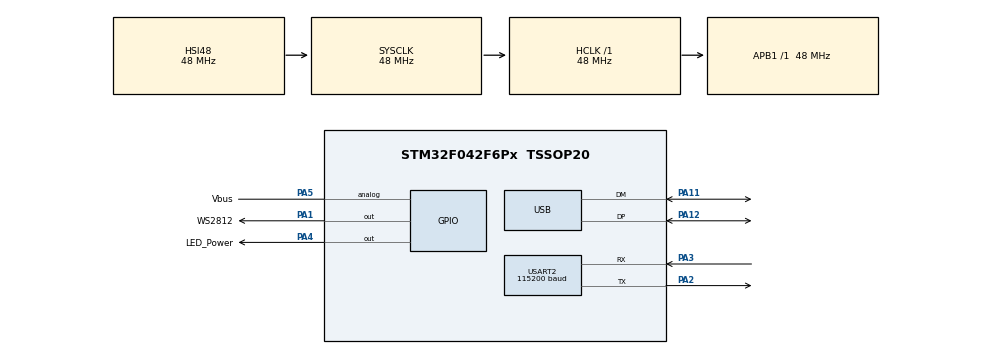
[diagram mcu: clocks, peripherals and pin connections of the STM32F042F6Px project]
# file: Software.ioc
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Mcu.Family=STM32F0
VP_SYS_VS_PINREMAP.Mode=PINREMAP
USB_DEVICE.CLASS_NAME_FS=CDC
NVIC.USB_IRQn=true\:0\:0\:false\:false\:true\:false\:true
USB_DEVICE.VirtualModeFS=Cdc_FS
VP_IWDG_VS_IWDG.Mode=IWDG_Activate
PA11.Mode=Device
USART2.BaudRate=115200
RCC.SYSCLKSource=RCC_SYSCLKSOURCE_HSI48
ProjectManager.StackSize=0x400
PA3.Mode=Asynchronous
PA13.Signal=SYS_SWDIO
PA12.Signal=USB_DP
PA4.PinState=GPIO_PIN_RESET
ProjectManager.TargetToolchain=Other Toolchains (GPDSC)
RCC.HCLKFreq_Value=48000000
VP_USB_DEVICE_VS_USB_DEVICE_CDC_FS.Mode=CDC_FS
VP_RCC_USB.Mode=CRS SYNC Source USB
PA1.GPIO_PuPd=GPIO_NOPULL
PA1.Signal=GPIO_Output
RCC.AHBFreq_Value=48000000
PF0-OSC_IN.Mode=HSE-External-Oscillator
PA5.Signal=SharedAnalog_PA5
PA4.GPIO_PuPd=GPIO_NOPULL
board=custom
USART2.VirtualMode-Asynchronous=VM_ASYNC
PA4.GPIO_Speed=GPIO_SPEED_FREQ_LOW
PA14.Mode=Serial_Wire
PA1.GPIO_Speed=GPIO_SPEED_FREQ_LOW
PA1.GPIO_Label=WS2812
PA13.Mode=Serial_Wire
Mcu.Name=STM32F042F6Px
PA2.Signal=USART2_TX
PA4.Signal=GPIO_Output
RCC.SYSCLKFreq_VALUE=48000000
Mcu.Package=TSSOP20
PA12.Mode=Device
PA5.GPIO_Label=Vbus
PA11.Signal=USB_DM
USB_DEVICE.APP_TX_DATA_SIZE=512
PA14.Signal=SYS_SWCLK
ProjectManager.HeapSize=0x200
PA1.PinState=GPIO_PIN_RESET
PA4.GPIO_ModeDefaultOutputPP=GPIO_MODE_OUTPUT_PP
SH.SharedAnalog_PA5.1=ADC_IN5
SH.SharedAnalog_PA5.0=GPIO_Analog
USB_DEVICE.APP_RX_DATA_SIZE=512
RCC.APB1TimFreq_Value=48000000
PA2.Mode=Asynchronous
PF0-OSC_IN.Signal=RCC_OSC_IN
PF1-OSC_OUT.Mode=HSE-External-Oscillator
RCC.APB1Freq_Value=48000000
USB_DEVICE.VirtualMode=Cdc
PA4.GPIO_Label=LED_Power
PF1-OSC_OUT.Signal=RCC_OSC_OUT
USB_DEVICE.USBD_DEBUG_LEVEL=2
PA3.Signal=USART2_RX
PA1.GPIO_ModeDefaultOutputPP=GPIO_MODE_OUTPUT_PP

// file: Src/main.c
/* USER CODE BEGIN Header */
/**
  ******************************************************************************
  * @file           : main.c
  * @brief          : Main program body
  ******************************************************************************
  * @attention
  *
  * <h2><center>&copy; Copyright (c) 2020 STMicroelectronics.
  * All rights reserved.</center></h2>
  *
  * This software component is licensed by ST under Ultimate Liberty license
  * SLA0044, the "License"; You may not use this file except in compliance with
  * the License. You may obtain a copy of the License at:
  *                             www.st.com/SLA0044
  *
  ******************************************************************************
  */
/* USER CODE END Header */

#include "main.h"
#include "iwdg.h"
#include "usart.h"
#include "usb_device.h"
#include "gpio.h"

void SystemClock_Config(void);

int main(void)
{

  /* MCU Configuration--------------------------------------------------------*/

  /* Reset of all peripherals, Initializes the Flash interface and the Systick. */
  HAL_Init();

  /* Configure the system clock */
  SystemClock_Config();

  /* Initialize all configured peripherals */
  MX_GPIO_Init();
  //MX_IWDG_Init();
  MX_USART2_UART_Init();
  MX_USB_DEVICE_Init();

  /* Infinite loop */
  /* USER CODE BEGIN WHILE */
  while (1)
  {
    //HAL_GPIO_WritePin(LED_Power_GPIO_Port, LED_Power_Pin, GPIO_PIN_RESET);
    HAL_GPIO_TogglePin(LED_Power_GPIO_Port, LED_Power_Pin);
    HAL_Delay(500);

    /* USER CODE END WHILE */

  }
}

void SystemClock_Config(void)
{
  RCC_OscInitTypeDef RCC_OscInitStruct = {0};
  RCC_ClkInitTypeDef RCC_ClkInitStruct = {0};
  RCC_PeriphCLKInitTypeDef PeriphClkInit = {0};
  RCC_CRSInitTypeDef RCC_CRSInitStruct = {0};

  /** Initializes the CPU, AHB and APB busses clocks
  */
  RCC_OscInitStruct.OscillatorType = RCC_OSCILLATORTYPE_HSI48|RCC_OSCILLATORTYPE_LSI;
  RCC_OscInitStruct.HSI48State = RCC_HSI48_ON;
  RCC_OscInitStruct.LSIState = RCC_LSI_ON;
  RCC_OscInitStruct.PLL.PLLState = RCC_PLL_NONE;
  if (HAL_RCC_OscConfig(&RCC_OscInitStruct) != HAL_OK)
  {
    Error_Handler();
  }
  /** Initializes the CPU, AHB and APB busses clocks
  */
  RCC_ClkInitStruct.ClockType = RCC_CLOCKTYPE_HCLK|RCC_CLOCKTYPE_SYSCLK
                              |RCC_CLOCKTYPE_PCLK1;
  RCC_ClkInitStruct.SYSCLKSource = RCC_SYSCLKSOURCE_HSI48;
  RCC_ClkInitStruct.AHBCLKDivider = RCC_SYSCLK_DIV1;
  RCC_ClkInitStruct.APB1CLKDivider = RCC_HCLK_DIV1;

  if (HAL_RCC_ClockConfig(&RCC_ClkInitStruct, FLASH_LATENCY_1) != HAL_OK)
  {
    Error_Handler();
  }
  PeriphClkInit.PeriphClockSelection = RCC_PERIPHCLK_USB;
  PeriphClkInit.UsbClockSelection = RCC_USBCLKSOURCE_HSI48;

  if (HAL_RCCEx_PeriphCLKConfig(&PeriphClkInit) != HAL_OK)
  {
    Error_Handler();
  }
  /** Enable the SYSCFG APB clock
  */
  __HAL_RCC_CRS_CLK_ENABLE();
  /** Configures CRS
  */
  RCC_CRSInitStruct.Prescaler = RCC_CRS_SYNC_DIV1;
  RCC_CRSInitStruct.Source = RCC_CRS_SYNC_SOURCE_USB;
  RCC_CRSInitStruct.Polarity = RCC_CRS_SYNC_POLARITY_RISING;
  RCC_CRSInitStruct.ReloadValue = __HAL_RCC_CRS_RELOADVALUE_CALCULATE(48000000,1000);
  RCC_CRSInitStruct.ErrorLimitValue = 34;
  RCC_CRSInitStruct.HSI48CalibrationValue = 32;

  HAL_RCCEx_CRSConfig(&RCC_CRSInitStruct);
}

void Error_Handler(void)
{
}

/************************ (C) COPYRIGHT STMicroelectronics *****END OF FILE****/
